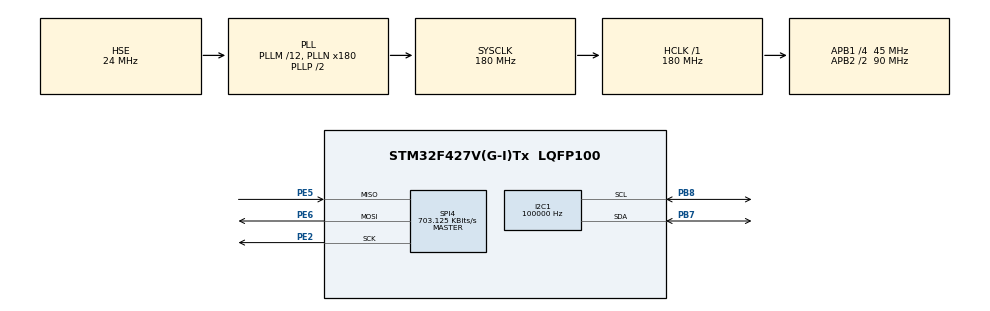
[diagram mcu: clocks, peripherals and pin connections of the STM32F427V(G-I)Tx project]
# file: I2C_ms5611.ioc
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I2C1.ClockSpeed=100000
I2C1.I2C_Mode=I2C_Fast
Mcu.Family=STM32F4
Mcu.Name=STM32F427V(G-I)Tx
Mcu.Package=LQFP100
NVIC.PriorityGroup=NVIC_PRIORITYGROUP_4
PA13.Mode=Serial_Wire
PA13.Signal=SYS_JTMS-SWDIO
PA14.Mode=Serial_Wire
PA14.Signal=SYS_JTCK-SWCLK
PB7.Mode=I2C
PB7.Signal=I2C1_SDA
PB8.Mode=I2C
PB8.Signal=I2C1_SCL
PE2.Mode=Full_Duplex_Master
PE2.Signal=SPI4_SCK
PE5.Mode=Full_Duplex_Master
PE5.Signal=SPI4_MISO
PE6.Mode=Full_Duplex_Master
PE6.Signal=SPI4_MOSI
PH0/OSC_IN.Mode=HSE-External-Oscillator
PH0/OSC_IN.Signal=RCC_OSC_IN
PH1/OSC_OUT.Mode=HSE-External-Oscillator
PH1/OSC_OUT.Signal=RCC_OSC_OUT
ProjectManager.HeapSize=0x200
ProjectManager.StackSize=0x400
ProjectManager.TargetToolchain=MDK-ARM V5
RCC.48MHZClocksFreq_Value=90000000
RCC.AHBFreq_Value=180000000
RCC.APB1CLKDivider=RCC_HCLK_DIV4
RCC.APB1Freq_Value=45000000
RCC.APB1TimFreq_Value=90000000
RCC.APB2CLKDivider=RCC_HCLK_DIV2
RCC.APB2Freq_Value=90000000
RCC.APB2TimFreq_Value=180000000
RCC.CortexFreq_Value=180000000
RCC.HCLKFreq_Value=180000000
RCC.HSE_VALUE=24000000
RCC.HSI_VALUE=16000000
RCC.LSE_VALUE=32768
RCC.PLLM=12
RCC.PLLN=180
RCC.PLLSourceVirtual=RCC_PLLSOURCE_HSE
RCC.SYSCLKFreq_VALUE=180000000
RCC.SYSCLKSource=RCC_SYSCLKSOURCE_PLLCLK
RCC.VCOOutputFreq_Value=360000000
SPI4.BaudRatePrescaler=SPI_BAUDRATEPRESCALER_128
SPI4.CalculateBaudRate=703.125 KBits/s
SPI4.Direction=SPI_DIRECTION_2LINES
SPI4.Mode=SPI_MODE_MASTER
SPI4.VirtualType=VM_MASTER
board=custom

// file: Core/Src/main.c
/* USER CODE BEGIN Header */
/**
  ******************************************************************************
  * @file           : main.c
  * @brief          : Main program body
  ******************************************************************************
  * @attention
  *
  * <h2><center>&copy; Copyright (c) 2022 STMicroelectronics.
  * All rights reserved.</center></h2>
  *
  * This software component is licensed by ST under BSD 3-Clause license,
  * the "License"; You may not use this file except in compliance with the
  * License. You may obtain a copy of the License at:
  *                        opensource.org/licenses/BSD-3-Clause
  *
  ******************************************************************************
  */
/* USER CODE END Header */
#include "main.h"
#include "i2c.h"
#include "spi.h"
#include "gpio.h"

/* USER CODE BEGIN Includes */
#include "ms5611.h"

/* USER CODE END Includes */

void SystemClock_Config(void);

int main(void)
{

  /* MCU Configuration--------------------------------------------------------*/

  /* Reset of all peripherals, Initializes the Flash interface and the Systick. */
  HAL_Init();

  /* Configure the system clock */
  SystemClock_Config();

  /* Initialize all configured peripherals */
  MX_GPIO_Init();
  MX_I2C1_Init();
  MX_SPI4_Init();

  /* Infinite loop */
  /* USER CODE BEGIN WHILE */
  while (1)
  {
      MS5611_INIT();
      GetPressandTemp();
      MS5611_Calculate_Val();
      relative_height();
    /* USER CODE END WHILE */

  }
}

void SystemClock_Config(void)
{
  RCC_OscInitTypeDef RCC_OscInitStruct = {0};
  RCC_ClkInitTypeDef RCC_ClkInitStruct = {0};

  /** Configure the main internal regulator output voltage
  */
  __HAL_RCC_PWR_CLK_ENABLE();
  __HAL_PWR_VOLTAGESCALING_CONFIG(PWR_REGULATOR_VOLTAGE_SCALE1);
  /** Initializes the RCC Oscillators according to the specified parameters
  * in the RCC_OscInitTypeDef structure.
  */
  RCC_OscInitStruct.OscillatorType = RCC_OSCILLATORTYPE_HSE;
  RCC_OscInitStruct.HSEState = RCC_HSE_ON;
  RCC_OscInitStruct.PLL.PLLState = RCC_PLL_ON;
  RCC_OscInitStruct.PLL.PLLSource = RCC_PLLSOURCE_HSE;
  RCC_OscInitStruct.PLL.PLLM = 12;
  RCC_OscInitStruct.PLL.PLLN = 180;
  RCC_OscInitStruct.PLL.PLLP = RCC_PLLP_DIV2;
  RCC_OscInitStruct.PLL.PLLQ = 4;
  if (HAL_RCC_OscConfig(&RCC_OscInitStruct) != HAL_OK)
  {
    Error_Handler();
  }
  /** Activate the Over-Drive mode
  */
  if (HAL_PWREx_EnableOverDrive() != HAL_OK)
  {
    Error_Handler();
  }
  /** Initializes the CPU, AHB and APB buses clocks
  */
  RCC_ClkInitStruct.ClockType = RCC_CLOCKTYPE_HCLK|RCC_CLOCKTYPE_SYSCLK
                              |RCC_CLOCKTYPE_PCLK1|RCC_CLOCKTYPE_PCLK2;
  RCC_ClkInitStruct.SYSCLKSource = RCC_SYSCLKSOURCE_PLLCLK;
  RCC_ClkInitStruct.AHBCLKDivider = RCC_SYSCLK_DIV1;
  RCC_ClkInitStruct.APB1CLKDivider = RCC_HCLK_DIV4;
  RCC_ClkInitStruct.APB2CLKDivider = RCC_HCLK_DIV2;

  if (HAL_RCC_ClockConfig(&RCC_ClkInitStruct, FLASH_LATENCY_5) != HAL_OK)
  {
    Error_Handler();
  }
}

void Error_Handler(void)
{
  __disable_irq();
  while (1)
  {
  }
}

/************************ (C) COPYRIGHT STMicroelectronics *****END OF FILE****/
